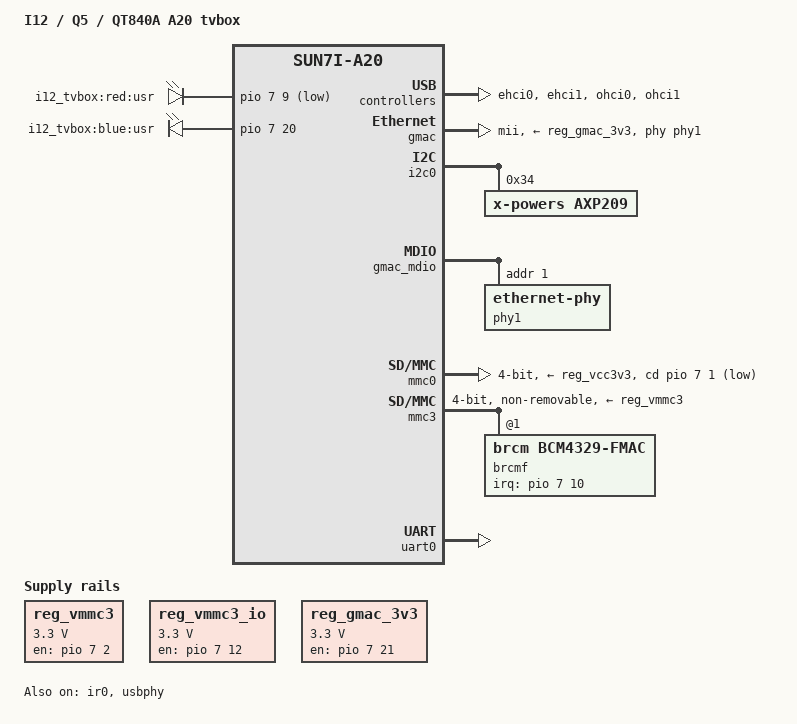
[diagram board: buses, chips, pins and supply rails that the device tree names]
/dts-v1/;
#include "sun7i-a20.dtsi"
#include "sunxi-common-regulators.dtsi"
#include <dt-bindings/gpio/gpio.h>
#include <dt-bindings/interrupt-controller/irq.h>
/ {
	model = "I12 / Q5 / QT840A A20 tvbox";
	compatible = "allwinner,i12-tvbox", "allwinner,sun7i-a20";
	aliases {
		serial0 = &uart0;
	};
	chosen {
		stdout-path = "serial0:115200n8";
	};
	leds {
		compatible = "gpio-leds";
		led-0 {
			label = "i12_tvbox:red:usr";
			gpios = <&pio 7 9 GPIO_ACTIVE_LOW>;
		};
		led-1 {
			label = "i12_tvbox:blue:usr";
			gpios = <&pio 7 20 GPIO_ACTIVE_HIGH>;
		};
	};
	reg_vmmc3: vmmc3 {
		compatible = "regulator-fixed";
		regulator-name = "vmmc3";
		regulator-min-microvolt = <3300000>;
		regulator-max-microvolt = <3300000>;
		enable-active-high;
		gpio = <&pio 7 2 GPIO_ACTIVE_HIGH>;
	};
	reg_vmmc3_io: vmmc3-io {
		compatible = "regulator-fixed";
		regulator-name = "vmmc3-io";
		regulator-min-microvolt = <3300000>;
		regulator-max-microvolt = <3300000>;
		regulator-always-on;
		enable-active-high;
		gpio = <&pio 7 12 GPIO_ACTIVE_HIGH>;
	};
	reg_gmac_3v3: gmac-3v3 {
		compatible = "regulator-fixed";
		regulator-name = "gmac-3v3";
		regulator-min-microvolt = <3300000>;
		regulator-max-microvolt = <3300000>;
		startup-delay-us = <50000>;
		enable-active-high;
		gpio = <&pio 7 21 GPIO_ACTIVE_HIGH>;
	};
};
&ehci0 {
	status = "okay";
};
&ehci1 {
	status = "okay";
};
&gmac {
	pinctrl-names = "default";
	pinctrl-0 = <&gmac_mii_pins>;
	phy-handle = <&phy1>;
	phy-mode = "mii";
	phy-supply = <&reg_gmac_3v3>;
	status = "okay";
};
&i2c0 {
	status = "okay";
	axp209: pmic@34 {
		compatible = "x-powers,axp209";
		reg = <0x34>;
		interrupt-parent = <&nmi_intc>;
		interrupts = <0 IRQ_TYPE_LEVEL_LOW>;
		interrupt-controller;
		#interrupt-cells = <1>;
	};
};
&ir0 {
	pinctrl-names = "default";
	pinctrl-0 = <&ir0_rx_pin>;
	status = "okay";
};
&gmac_mdio {
	phy1: ethernet-phy@1 {
		reg = <1>;
	};
};
&mmc0 {
	vmmc-supply = <&reg_vcc3v3>;
	bus-width = <4>;
	cd-gpios = <&pio 7 1 GPIO_ACTIVE_LOW>;  
	status = "okay";
};
&mmc3 {
	vmmc-supply = <&reg_vmmc3>;
	bus-width = <4>;
	non-removable;
	status = "okay";
	brcmf: wifi@1 {
		reg = <1>;
		compatible = "brcm,bcm4329-fmac";
		interrupt-parent = <&pio>;
		interrupts = <7 10 IRQ_TYPE_LEVEL_LOW>;  
		interrupt-names = "host-wake";
	};
};
&ohci0 {
	status = "okay";
};
&ohci1 {
	status = "okay";
};
&reg_usb1_vbus {
	status = "okay";
};
&reg_usb2_vbus {
	status = "okay";
};
&uart0 {
	pinctrl-names = "default";
	pinctrl-0 = <&uart0_pb_pins>;
	status = "okay";
};
&usbphy {
	usb1_vbus-supply = <&reg_usb1_vbus>;
	usb2_vbus-supply = <&reg_usb2_vbus>;
	status = "okay";
};
